# N575F145_v1 register map
File version: 1.0
Registers are 32-bit, read-write, reset 0x0 unless marked. A register's access mark holds for its fields unless they carry their own. Offsets are from the block's base; [hi:lo] are bit positions.

## I2S — I2S Register Map
Base 0x400A0000
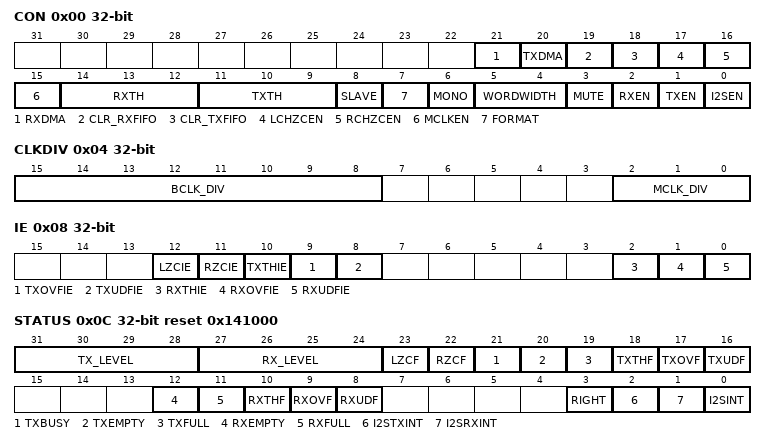
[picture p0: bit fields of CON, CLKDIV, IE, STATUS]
0x00 CON — I2S Control Register
  [21] RXDMA — Enable Receive DMA. When RX DMA is enabled, I2S requests DMA to transfer data from receive FIFO to SRAM if FIFO is not empty.
    0=Disable RX DMA; 1=Enable RX DMA
  [20] TXDMA — Enable Transmit DMA. When TX DMA is enables, I2S request DMA to transfer data from SRAM to transmit FIFO if FIFO is not full.
    0=Disable TX DMA; 1=Enable TX DMA
  [19] CLR_RXFIFO — Clear Receive FIFO. Write 1 to clear receive FIFO, internal pointer is reset to FIFO start point, and RXFIFO_LEVEL[3:0] returns to zero and receive FIFO becomes empty. This bit is cleared by hardware automatically when clear operation complete.
  [18] CLR_TXFIFO — Clear Transmit FIFO. Write 1 to clear transmit FIFO, internal pointer is reset to FIFO start point, and TXFIFO_LEVEL[3:0] returns to zero and transmit FIFO becomes empty. Data in transmit FIFO is not changed. This bit is cleared by hardware automatically when clear operation complete.
  [17] LCHZCEN — Left Channel Zero Cross Detect Enable. If this bit is set to 1, when left channel data sign bit changes, or data bits are all zero, the LZCF flag in I2S_STATUS register will be set to 1.
    0=Disable left channel zero cross detect; 1=Enable left channel zero cross detect
  [16] RCHZCEN — Right Channel Zero Cross Detect Enable. If this bit is set to 1, when right channel data sign bit changes, or data bits are all zero, the RZCF flag in I2S_STATUS register will be set to 1.
    0=Disable right channel zero cross detect; 1=Enable right channel zero cross detect
  [15] MCLKEN — Master Clock Enable. The ISD9160 can generate a master clock signal to an external audio CODEC to synchronize the audio devices. If audio devices are not synchronous, then data will be periodically corrupted. Software needs to implement a way to drop/repeat or interpolate samples in a jitter buffer if devices are not synchronized. The master clock frequency is determined by the CLKDIV.MCLK_DIV[2:0] register.
    0=Disable master clock; 1=Enable master clock
  [14:12] RXTH — Receive FIFO Threshold Level. When received data word(s) in buffer is equal or higher than threshold level then RXTHI flag is set.
  [11:9] TXTH — Transmit FIFO Threshold Level. If remaining data words in transmit FIFO less than or equal to the threshold level then TXTHI flag is set.
  [8] SLAVE — Slave Mode. I2S can operate as a master or slave. For master mode, I2S_BCLK and I2S_FS pins are outputs and send bit clock and frame sync from ISD9160. In slave mode, I2S_BCLK and I2S_FS pins are inputs and bit clock and frame sync are received from external audio device.
    0=Master mode; 1=Slave mode
  [7] FORMAT — Data format. See Figure 561 and Figure 562 for timing differences.
    0=I2S data format; 1=MSB justified data format
  [6] MONO — Monaural data. This parameter sets whether mono or stereo data is processed. See Figure 563 for details of how data is formatted in transmit and receive FIFO.
    0=Data is stereo format; 1=Data is monaural format
  [5:4] WORDWIDTH — Word Width. This parameter sets the word width of audio data. See Figure 563 for details of how data is formatted in transmit and receive FIFO.
    0=data is 8 bit; 1=data is 16 bit; 2=data is 24 bit; 3=data is 32 bit
  [3] MUTE — Transmit Mute Enable
    0=Transmit data is shifted from FIFO; 1=Transmit channel zero
  [2] RXEN — Receive Enable
    0=Disable data receive; 1=Enable data receive
  [1] TXEN — Transmit Enable
    0=Disable data transmit; 1=Enable data transmit
  [0] I2SEN — Enable I2S Controller
    0=Disable; 1=Enable
0x04 CLKDIV — I2S Clock Divider Register
  [15:8] BCLK_DIV — Bit Clock Divider. If I2S operates in master mode, bit clock is provided by ISD9160. Software can program these bits to generate bit clock frequency for the desired sample rate. For sample rate Fs, the desired bit clock frequency is: F(BCLK) = Fs x Word_width_in_bytes x 16. For example if Fs = 16kHz, and word width is 2-bytes (16bit) then desired bit clock frequency is 512kHz. The bit clock frequency is given by: F(BCLK) = F(I2S_CLK) / 2x(BCLK_DIV+1). Or, BCLK_DIV = F(I2S_CLK) / (2 x F(BCLK)) -1. So if F(I2S_CLK) = HCLK = 49.152MHz , desired F(BCLK) = 512kHz then BCLK_DIV = 47
  [2:0] MCLK_DIV — Master Clock Divider. ISD9160 can generate a master clock to synchronously drive an external audio device. If MCLK_DIV is set to 0, MCLK is the same as I2S_CLK clock input, otherwise MCLK frequency is given by: F(MCLK) = F(I2S_CLK) / (2xMCLK_DIV). Or, MCLK_DIV = F(I2S_CLK) / (2 x F(MCLK)). If the desired MCLK frequency is 254Fs and Fs = 16kHz then MCLK_DIV = 6
0x08 IE — I2S Interrupt Enable Register
  [all] fields
    0=Disable interrupt; 1=Enable interrupt
  [12] LZCIE — Left Channel Zero Cross Interrupt Enable. Interrupt will occur if this bit is set to 1 and left channel has zero cross event
  [11] RZCIE — Right Channel Zero Cross Interrupt Enable. Interrupt will occur if this bit is set to 1 and right channel has zero cross event
  [10] TXTHIE — Transmit FIFO Threshold Level Interrupt Enable. Interrupt occurs if this bit is set to 1 and data words in transmit FIFO is less than TXTH[2:0].
  [9] TXOVFIE — Transmit FIFO Overflow Interrupt Enable. Interrupt occurs if this bit is set to 1 and transmit FIFO overflow flag is set to 1
  [8] TXUDFIE — Transmit FIFO Underflow Interrupt Enable. Interrupt occur if this bit is set to 1 and transmit FIFO underflow flag is set to 1.
  [2] RXTHIE — Receive FIFO Threshold Level Interrupt. Interrupt occurs if this bit is set to 1 and data words in receive FIFO is greater than or equal to RXTH[2:0].
  [1] RXOVFIE — Receive FIFO Overflow Interrupt Enable
  [0] RXUDFIE — Receive FIFO Underflow Interrupt Enable. If software read receive FIFO when it is empty then RXUDF flag in I2SSTATUS register is set to 1.
0x0C STATUS reset 0x141000 — I2S Status Register
  [31:28] TX_LEVEL ro — Transmit FIFO level (Read Only)
  [27:24] RX_LEVEL ro — Receive FIFO level (Read Only)
  [23] LZCF — Left channel zero cross flag (write '1' to clear, or clear LCHZCEN)
    0=No zero cross detected; 1=Left channel zero cross is detected
  [22] RZCF — Right channel zero cross flag (write '1' to clear, or clear RCHZCEN)
    0=No zero cross; 1=Right channel zero cross is detected
  [21] TXBUSY ro — Transmit Busy (Read Only). This bit is cleared when all data in transmit FIFO and Tx shift register is shifted out. It is set when first data is loaded to Tx shift register.
    0=Transmit shift register is empty; 1=Transmit shift register is busy
  [20] TXEMPTY ro — Transmit FIFO Empty (Read Only). This is set when transmit FIFO is empty.
    0=Not empty; 1=Empty
  [19] TXFULL ro — Transmit FIFO Full (Read Only). This bit is set when transmit FIFO is full.
    0=Not full; 1=Full
  [18] TXTHF ro — Transmit FIFO Threshold Flag (Read Only). When data word(s) in transmit FIFO is less than or equal to the threshold value set in TXTH[2:0] the TXTHF bit becomes to 1. It remains set until transmit FIFO level is greater than TXTH[2:0]. Cleared by writing to TXFIFO register until threshold exceeded.
    0=Data word(s) in FIFO is greater than threshold level; 1=Data word(s) in FIFO is less than or equal to threshold level
  [17] TXOVF — Transmit FIFO Overflow Flag (Write '1' to clear). This flag is set if data is written to transmit FIFO when it is full.
    0=No overflow; 1=Overflow
  [16] TXUDF — Transmit FIFO underflow flag (Write '1' to clear). This flag is set if I2S controller requests data when transmit FIFO is empty.
    0=No underflow; 1=Underflow
  [12] RXEMPTY ro — Receive FIFO empty (Read Only). This is set when receive FIFO is empty.
    0=Not empty; 1=Empty
  [11] RXFULL ro — Receive FIFO full (Read Only). This bit is set when receive FIFO is full.
    0=Not full; 1=Full
  [10] RXTHF ro — Receive FIFO Threshold Flag (Read Only). When data word(s) in receive FIFO is greater than or equal to threshold value set in RXTH[2:0] the RXTHF bit becomes to 1. It remains set until receive FIFO level is less than RXTH[2:0]. It is cleared by reading RXFIFO until threshold satisfied.
    0=Data word(s) in FIFO is less than threshold level; 1=Data word(s) in FIFO is greater than or equal to threshold level
  [9] RXOVF — Receive FIFO Overflow Flag (Write '1' to clear). This flag is set if I2S controller writes to receive FIFO when it is full. Audio data is lost.
    0=No overflow; 1=Overflow
  [8] RXUDF — Receive FIFO Underflow Flag (Write '1' to clear). This flag is set if attempt is made to read receive FIFO while it is empty.
    0=No underflow; 1=Underflow
  [3] RIGHT ro — Right Channel Active (Read Only). This bit indicates current data being transmitted/received belongs to right channel
    0=Left channel; 1=Right channel
  [2] I2STXINT ro — I2S Transmit Interrupt (Read Only). This indicates that there is an active transmit interrupt source. This could be TXOVF, TXUDF, TXTHF, LZCF or RZCF if corresponding interrupt enable bits are active. To clear interrupt the corresponding source(s) must be cleared.
    0=No transmit interrupt; 1=Transmit interrupt occurred
  [1] I2SRXINT ro — I2S Receive Interrupt (Read Only). This indicates that there is an active receive interrupt source. This could be RXOVF, RXUDF or RXTHF if corresponding interrupt enable bits are active. To clear interrupt the corresponding source(s) must be cleared.
    0=No receive interrupt; 1=Receive interrupt occurred
  [0] I2SINT ro — I2S Interrupt (Read Only). This bit is set if any enabled I2S interrupt is active.
    0=No I2S interrupt; 1=I2S interrupt active
0x10 TXFIFO wo — I2S Transmit FIFO Register
  [31:0] TXFIFO — Transmit FIFO Register (Write Only). A write to this register pushes data onto the transmit FIFO. The transmit FIFO is eight words deep. The number of words currently in the FIFO can be determined by reading I2S->STATUS.TX_LEVEL.
0x14 RXFIFO ro — I2S Receive FIFO Register
  [31:0] RXFIFO — Receive FIFO Register (Read Only). A read of this register will pop data from the receive FIFO. The receive FIFO is eight words deep. The number of words currently in the FIFO can be determined by reading I2S->STATUS.RX_LEVEL.
